# STM32U3B5xx register map
File version: 1.0
Registers are 32-bit, read-write, reset 0x0 unless marked. A register's access mark holds for its fields unless they carry their own. Offsets are from the block's base; [hi:lo] are bit positions; lines under a group give offsets from that group; {n}, {i} and the like mark numbered series; <NAME> marks a mode.

## HSP1 — HSP
Base 0x4002C000
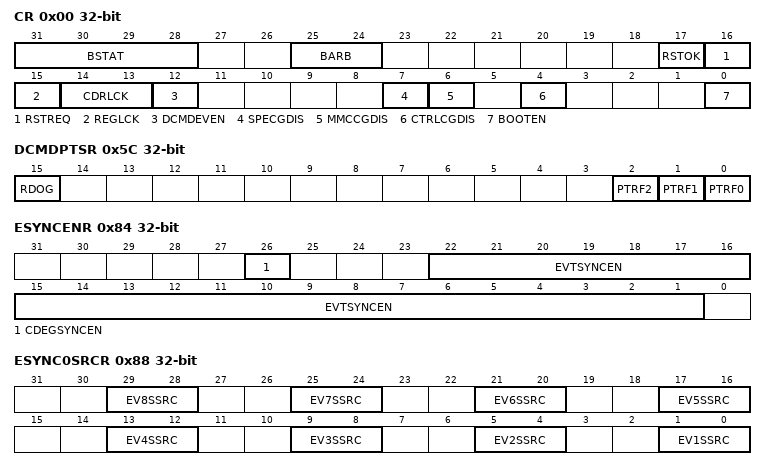
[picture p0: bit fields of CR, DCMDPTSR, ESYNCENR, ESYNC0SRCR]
0x00 CR — HSP control register
  [31:28] BSTAT — BSTAT[3:0] bits (Boot status)
  [25:24] BARB — BARB[1:0] bits (BRAM Arbitration)
  [17] RSTOK — RSTOK (Reset request accepted)
  [16] RSTREQ — RSTREQ (Reset request)
  [15] REGLCK — REGLCK (Register write lock access control)
  [14:13] CDRLCK — CDRLCK[1:0] bits (CRAM & DRAM lock access control)
  [12] DCMDEVEN — DCMDEVEN (Direct command event enable)
  [7] SPECGDIS — SPECGDIS (SPE clock gating disable)
  [6] MMCCGDIS — MMCCGDIS (MMC clock gating disable)
  [4] CTRLCGDIS — CTRLCGDIS (HSP_CTRL clock gating disable)
  [0] BOOTEN — BOOTEN (Boot Enable control)
0x40 C2HSEMR — HSP CPU to HSP semaphore register
  [0] C2HSEM — C2HSEM (CPU to HSP semaphore)
0x44 C2HMSGDR — HSP CPU to HSP message data register
  [31:0] C2HDATA — C2HDATA[31:0] bits (CPU Message for the HSP)
0x48 H2CSEMR — HSP HSP to CPU semaphore register
  [0] H2CSEM — H2CSEM (HSP to CPU semaphore)
0x4C H2CMSGDR — HSP HSP to CPU message data register
  [31:0] H2CDATA — H2CDATA[31:0] bits (HSP Message for the CPU)
0x58 DCMDSR — HSP DCMD Command status register
  [0] DCBSY — DCBSY (Direct command busy flag)
0x5C DCMDPTSR — HSP DCMD Pointer status register
  [15] RDOG — RDOG (Read on-going indicator)
  [2] PTRF2 — PTRF2 (Address pointer 2 flag)
  [1] PTRF1 — PTRF1 (Address pointer 1 flag)
  [0] PTRF0 — PTRF0 (Address pointer 0 flag)
0x60 DCMDIDR — HSP DCMD Command ID register
  [15:0] CMDID — CMDID[15:0] bits (Command ID)
{0x64+4i} DCMDPTR{i} (i=0..2) — HSP DCMD address pointer register {i}
  [31:0] PTCPU — PTCPU[31:0] bits (Address pointer value)
0x80 EVTENR — HSP event enable register
  [22:1] EVTEN — EVTEN[21:0] bits (Events enable)
0x84 ESYNCENR — HSP Event synchronization enable register
  [26] CDEGSYNCEN — CDEGSYNCEN (CPU dedicated event synchronization enable)
  [22:1] EVTSYNCEN — EVTSYNCEN[21:0] bits (Event synchronization enable)
0x88 ESYNC0SRCR — HSP Event synchronization source register 0
  [4n-3:4n-4] EV{n}SSRC (n=1..8) — EV{n}SSRC[1:0] bits (Event {n} synchronization source)
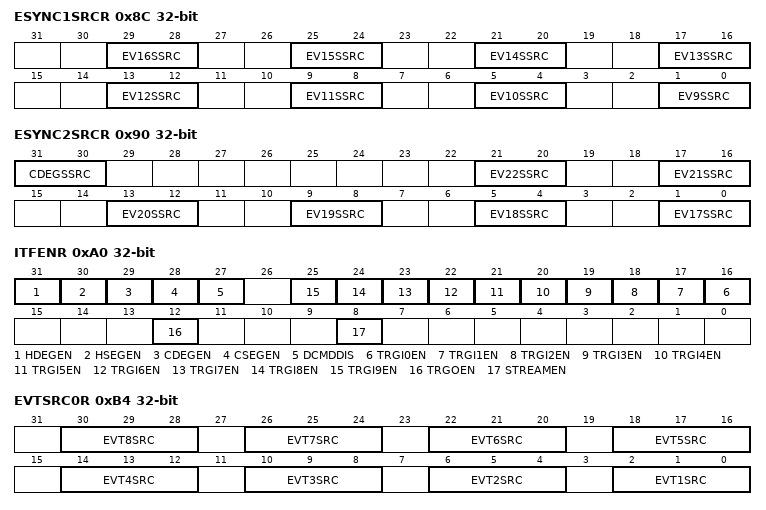
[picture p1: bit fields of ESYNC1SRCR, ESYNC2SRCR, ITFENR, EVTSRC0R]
0x8C ESYNC1SRCR — HSP Event synchronization source register 1
  [4n-35:4n-36] EV{n}SSRC (n=9..16) — EV{n}SSRC[1:0] bits (Event {n} synchronization source)
0x90 ESYNC2SRCR — HSP Event synchronization source register 2
  [31:30] CDEGSSRC — CDEGSSRC[1:0] bits (CPU dedicated event synchronization source)
  [4n-67:4n-68] EV{n}SSRC (n=17..22) — EV{n}SSRC[1:0] bits (Event {n} synchronization source)
0x98 PEVTLR — HSP pending event level register
  [27:0] EVTL — EVTL[27:0] bits (Event level)
0xA0 ITFENR — HSP interfaces enable register
  [31] HDEGEN — HDEGEN (HDEG interface enable bit )
  [30] HSEGEN — HSEGEN (HSEG interface enable bit )
  [29] CDEGEN — CDEGEN (CDEG interface enable bit )
  [28] CSEGEN — CSEGEN (CSEG interface enable bit <sup>(1)</sup>)
  [27] DCMDDIS — DCMDDIS (Direct command interface disable bit )
  [n+16] TRGI{n}EN (n=0..9) — TRGI{n}EN (TRGIN{n} enable bit <sup>(1)</sup>)
  [12] TRGOEN — TRGOEN (TRGO enable bit <sup>(1)</sup>)
  [8] STREAMEN — STREAMEN (STREAMITF enable <sup>(1)</sup>)
0xB4 EVTSRC0R — HSP Event source register 0
  [4n-2:4n-4] EVT{n}SRC (n=1..8) — EVT{n}SRC[2:0] bits (Event source selection for priority encoder input {n})
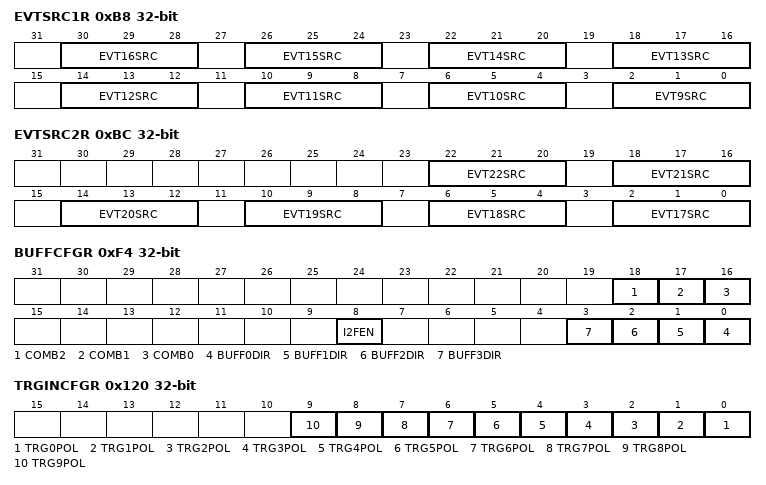
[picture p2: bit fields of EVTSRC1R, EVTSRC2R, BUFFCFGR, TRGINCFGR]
0xB8 EVTSRC1R — HSP Event source register 1
  [4n-34:4n-36] EVT{n}SRC (n=9..16) — EVT{n}SRC[2:0] bits (Event source selection for priority encoder input {n})
0xBC EVTSRC2R — HSP Event source register 2
  [4n-66:4n-68] EVT{n}SRC (n=17..22) — EVT{n}SRC[2:0] bits (Event source selection for priority encoder input {n})
0xF4 BUFFCFGR — HSP BUFF configuration register
  [18] COMB2 — COMB2 (BUFCMB control for buff_evt[2] )
  [17] COMB1 — COMB1 (BUFCMB control for buff_evt[1] <sup>(1)</sup>)
  [16] COMB0 — COMB0 (BUFCMB control for buff_evt[0] <sup>(1)</sup>)
  [8] I2FEN — I2FEN (integer to float32 conversion <sup>(1)</sup>)
  [n] BUFF{n}DIR (n=0..3) — BUFF{n}DIR (Direction selection of BUFF{n} <sup>(1)</sup>)
{0xF8+4i} BUFFDR{i} (i=0..3) — HSP BUFF data register array
  [31:0] BUFFDAT — BUFFDAT[31:0] bits (Data buffer)
0x120 TRGINCFGR — HSP TRGIN configuration register
  [n] TRG{n}POL (n=0..9) — TRG{n}POL (Polarity selection for TRGIN{n})
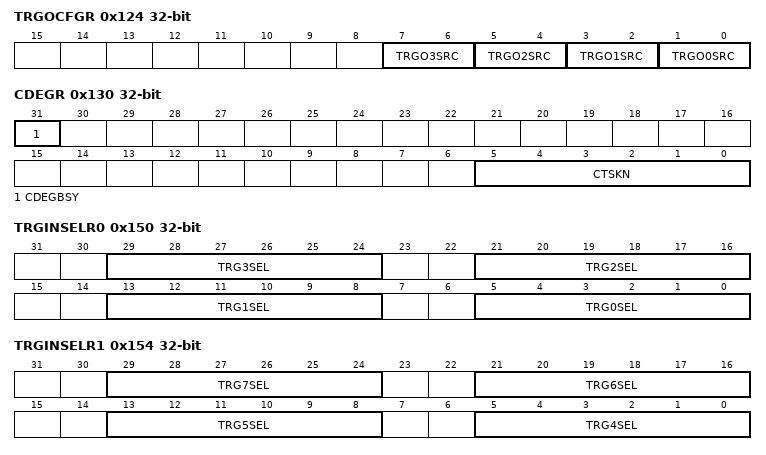
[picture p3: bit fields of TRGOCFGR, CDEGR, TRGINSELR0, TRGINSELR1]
0x124 TRGOCFGR — HSP TRGO configuration register
  [7:6] TRGO3SRC — TRGO3SRC[1:0] bits (Trigger source selection for hsp_trg_out[3] )
  [5:4] TRGO2SRC — TRGO2SRC[1:0] bits (Trigger source selection for hsp_trg_out[2] <sup>(1)</sup>)
  [3:2] TRGO1SRC — TRGO1SRC[1:0] bits (Trigger source selection for hsp_trg_out[1] <sup>(1)</sup>)
  [1:0] TRGO0SRC — TRGO0SRC[1:0] bits (Trigger source selection for hsp_trg_out[0] <sup>(1)</sup>)
0x12C CSEGR — HSP CPU shared event generator register
  [22:1] CSEVT — CSEVT[21:0] bits (CPU Shared Software Event )
0x130 CDEGR — HSP CPU dedicated event generation register
  [31] CDEGBSY — CDEGBSY (CPU dedicated event generator busy)
  [5:0] CTSKN — CTSKN[5:0] bits (CPU Task number)
0x150 TRGINSELR0 — HSP TRGIN input selection register 0
  [8n+5:8n] TRG{n}SEL (n=0..3) — TRG{n}SEL[5:0] bits (Input trigger selection for TRGIN{n})
0x154 TRGINSELR1 — HSP TRGIN input selection register 1
  [8n-27:8n-32] TRG{n}SEL (n=4..7) — TRG{n}SEL[5:0] bits (Input trigger selection for TRGIN{n})
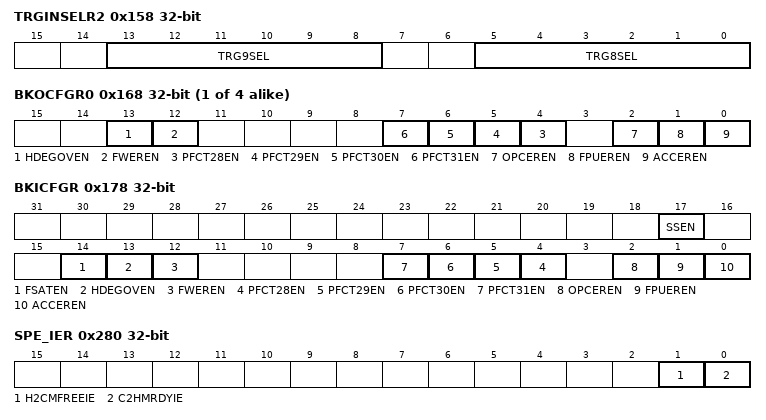
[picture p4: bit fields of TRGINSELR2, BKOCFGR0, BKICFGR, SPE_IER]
0x158 TRGINSELR2 — HSP TRGIN input selection register 2
  [13:8] TRG9SEL — TRG9SEL[5:0] bits (Input trigger selection for TRGIN9)
  [5:0] TRG8SEL — TRG8SEL[5:0] bits (Input trigger selection for TRGIN8)
{0x168+4i} BKOCFGR{i} (i=0..3) — HSP break output configuration register 0-3
  [13] HDEGOVEN — HDEGOVEN (HSP dedicated event generator overrun break enable for HDEGOVRF <sup>(1)</sup>)
  [12] FWEREN — FWEREN (Firmware error break enable for FWERRF <sup>(1)</sup>)
  [n-24] PFCT{n}EN (n=28..31) — PFCT{n}EN (Processing function flag break enable for PFCTF[{n}] <sup>(1)</sup>)
  [2] OPCEREN — OPCEREN (Opcode error break enable for OPCOERRF )
  [1] FPUEREN — FPUEREN (FPU error break enable for FPUERRF <sup>(1)</sup>)
  [0] ACCEREN — ACCEREN (Access error break enable for ACCERRF <sup>(1)</sup>)
0x178 BKICFGR — HSP break input configuration register
  [17] SSEN — SSEN (Single step enable <sup>(1)</sup>)
  [14] FSATEN — FSATEN (FPU saturation break enable for FPUSATF <sup>(1)</sup>)
  [13] HDEGOVEN — HDEGOVEN (HSP dedicated event generator overrun break enable for HDEGOVRF <sup>(1)</sup>)
  [12] FWEREN — FWEREN (Firmware error break enable for FWERRF <sup>(1)</sup>)
  [n-24] PFCT{n}EN (n=28..31) — PFCT{n}EN (Processing function flag break enable for PFCTF[{n}] <sup>(1)</sup>)
  [2] OPCEREN — OPCEREN (Opcode error break enable for OPCOERRF )
  [1] FPUEREN — FPUEREN (FPU error break enable for FPUERRF <sup>(1)</sup>)
  [0] ACCEREN — ACCEREN (Access error break enable for ACCERRF <sup>(1)</sup>)
0x188 FWERR — HSP firmware error register
  [9:0] FWERRN — FWERRN[9:0] bits (Firmware error number)
{0x194+4i} PARAMR{i} (i=0..15) — HSP parameter register {i}
  [31:0] PARAM — PARAM[31:0] bits (Parameter value)
0x280 SPE_IER — HSP SPE interrupt enable register
  [1] H2CMFREEIE — H2CMFREEIE (SPE to CPU message free interrupt enable)
  [0] C2HMRDYIE — C2HMRDYIE (CPU to SPE message ready interrupt enable)
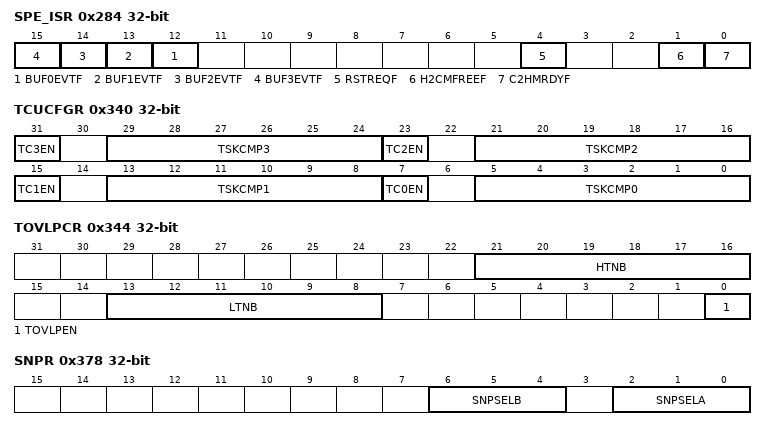
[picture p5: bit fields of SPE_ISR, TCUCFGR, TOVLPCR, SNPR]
0x284 SPE_ISR — HSP SPE interrupt status register
  [n+12] BUF{n}EVTF (n=0..3) — BUF{n}EVTF (BUF{n} status)
  [4] RSTREQF — RSTREQF (HSP reset request)
  [1] H2CMFREEF — H2CMFREEF (SPE to CPU message box status)
  [0] C2HMRDYF — C2HMRDYF (CPU to SPE message box status)
0x340 TCUCFGR — HSP task comparator unit register
  [31] TC3EN — TC3EN (Task comparator 3 enable )
  [8n+5:8n] TSKCMP{n} (n=0..3) — TSKCMP{n}[5:0] bits (Task compare {n} <sup>(1)</sup>)
  [23] TC2EN — TC2EN (Task comparator 2 enable <sup>(1)</sup>)
  [15] TC1EN — TC1EN (Task comparator 1 enable <sup>(1)</sup>)
  [7] TC0EN — TC0EN (Task comparator 0 enable <sup>(1)</sup>)
0x344 TOVLPCR — HSP task overlap control register
  [21:16] HTNB — HTNB[5:0] bits (Higher task number value )
  [13:8] LTNB — LTNB[5:0] bits (Lower task number value <sup>(1)</sup>)
  [0] TOVLPEN — TOVLPEN (Task overlap enable <sup>(1)</sup>)
0x378 SNPR — HSP snoop register
  [6:4] SNPSELB — SNPSELB[2:0] bits (Snoop group B signal selection)
  [2:0] SNPSELA — SNPSELA[2:0] bits (Snoop group A signal selection)
0x37C CCNTR — HSP conflict counter register
  [31:0] CCNTR — CCNTR[31:0] bits (Conflict counter)
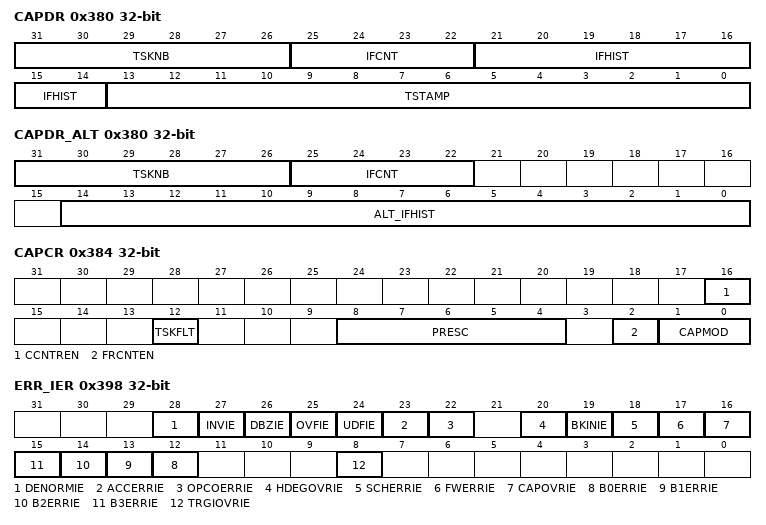
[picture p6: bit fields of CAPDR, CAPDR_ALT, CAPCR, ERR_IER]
0x380 CAPDR — HSP data capture register
  [31:26] TSKNB — Last captured task number
  [25:22] IFCNT — IF instruction counter
  [21:14] IFHIST — IF condition history
  [13:0] TSTAMP — Time-stamp value
0x380 CAPDR_ALT (alternate view of CAPDR) — HSP data capture register
  [31:26] TSKNB — Last captured task number
  [25:22] IFCNT — IF instruction counter
  [14:0] ALT_IFHIST — IF condition history
0x384 CAPCR — HSP capture control register
  [16] CCNTREN — CCNTREN (Conflict counter enable )
  [12] TSKFLT — TSKFLT (Task filter enable <sup>(1)</sup>)
  [8:4] PRESC — PRESC[4:0] bits (Time-stamp prescaler value )
  [2] FRCNTEN — FRCNTEN (Free-running counter enable )
  [1:0] CAPMOD — CAPMOD[1:0] bits (Capture mode )
0x398 ERR_IER — HSP error interrupt enable register
  [28] DENORMIE — DENORMIE (FPU denormal interrupt enable)
  [27] INVIE — INVIE (FPU Invalid exception interrupt enable)
  [26] DBZIE — DBZIE (FPU division-by-zero exception interrupt enable)
  [25] OVFIE — OVFIE (FPU Overflow exception interrupt enable)
  [24] UDFIE — UDFIE (FPU Underflow exception interrupt enable)
  [23] ACCERRIE — ACCERRIE (SPE access error interrupt enable)
  [22] OPCOERRIE — OPCOERRIE (Invalid Op. code error interrupt enable)
  [20] HDEGOVRIE — HDEGOVRIE (SPE event overrun interrupt enable)
  [19] BKINIE — BKINIE (Break input interrupt enable)
  [18] SCHERRIE — SCHERRIE (Scheduler error interrupt enable)
  [17] FWERRIE — FWERRIE (Firmware error interrupt enable)
  [16] CAPOVRIE — CAPOVRIE (Capture register overrun interrupt enable)
  [n+12] B{n}ERRIE (n=0..3) — B{n}ERRIE (H2CBUFF{n} underrun or C2HBUFF{n} overrun interrupt enable)
  [8] TRGIOVRIE — TRGIOVRIE (TRGITF overrun interrupt enable)
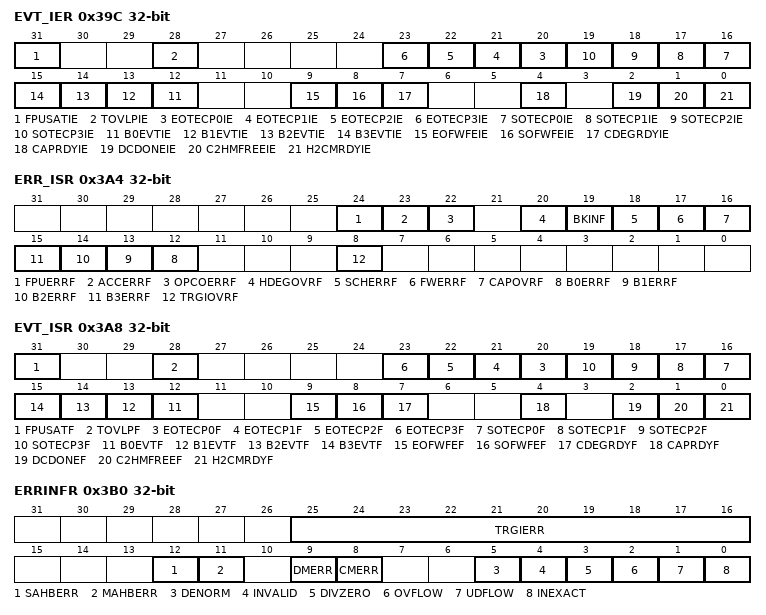
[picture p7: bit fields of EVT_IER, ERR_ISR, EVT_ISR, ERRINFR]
0x39C EVT_IER — HSP events interrupt enable register
  [31] FPUSATIE — FPUSATIE (Saturation flag interrupt enable)
  [28] TOVLPIE — TOVLPIE (Task overlap flag interrupt enable)
  [n+20] EOTECP{n}IE (n=0..3) — EOTECP{n}IE (End of task generated by event comparator {n} interrupt enable)
  [n+16] SOTECP{n}IE (n=0..3) — SOTECP{n}IE (Start of task generated by event comparator {n} interrupt enable)
  [n+12] B{n}EVTIE (n=0..3) — B{n}EVTIE (BUFF{n} event interrupt enable)
  [9] EOFWFEIE — EOFWFEIE (End of WFE interrupt enable)
  [8] SOFWFEIE — SOFWFEIE (Start of WFE interrupt enable)
  [7] CDEGRDYIE — CDEGRDYIE (CPU Dedicated event generator ready interrupt enable)
  [4] CAPRDYIE — CAPRDYIE (Capture buffer data ready interrupt enable)
  [2] DCDONEIE — DCDONEIE (Direct command done interrupt enable)
  [1] C2HMFREEIE — C2HMFREEIE (CPU to HSP message box free interrupt enable)
  [0] H2CMRDYIE — H2CMRDYIE (HSP to CPU message ready interrupt enable)
0x3A0 PFCTEVT_IER — HSP processing event interrupt enable register
  [31:0] PFCTIE — PFCTIE[31:0] bits (Processing function flags interrupt enable)
0x3A4 ERR_ISR — HSP error interrupt status register
  [24] FPUERRF — FPUERRF (Computation error flag)
  [23] ACCERRF — ACCERRF (SPE Access error flag)
  [22] OPCOERRF — OPCOERRF (Invalid OpCode error flag)
  [20] HDEGOVRF — HDEGOVRF (SPE event overrun flag)
  [19] BKINF — BKINF (Break input flag)
  [18] SCHERRF — SCHERRF (Scheduler error flag)
  [17] FWERRF — FWERRF (Firmware error flag)
  [16] CAPOVRF — CAPOVRF (Capture register overrun flag)
  [n+12] B{n}ERRF (n=0..3) — B{n}ERRF (H2CBUFF{n} underrun or C2HBUFF{n} overrun flag)
  [8] TRGIOVRF — TRGIOVRF (TRGITF overrun flag)
0x3A8 EVT_ISR — HSP events interrupt status register
  [31] FPUSATF — FPUSATF (FPU saturation flag)
  [28] TOVLPF — TOVLPF (Task overlap flag)
  [n+20] EOTECP{n}F (n=0..3) — EOTECP{n}F (End of task flag, for event comparator {n})
  [n+16] SOTECP{n}F (n=0..3) — SOTECP{n}F (Start of task flag, for event comparator {n})
  [n+12] B{n}EVTF (n=0..3) — B{n}EVTF (BUFF{n} event flag)
  [9] EOFWFEF — EOFWFEF (End of WFE flag)
  [8] SOFWFEF — SOFWFEF (Start of WFE flag)
  [7] CDEGRDYF — CDEGRDYF (CPU Dedicated event generator ready flag)
  [4] CAPRDYF — CAPRDYF (Capture buffer data ready flag)
  [2] DCDONEF — DCDONEF (Direct command done flag)
  [1] C2HMFREEF — C2HMFREEF (CPU to HSP message box free flag)
  [0] H2CMRDYF — H2CMRDYF (HSP to CPU message ready flag)
0x3AC PFCTEVT_ISR — HSP processing event interrupt status register
  [31:0] PFCTF — PFCTF[31:0] bits (Flags generated by SPE processing functions )
0x3B0 ERRINFR — HSP error information register
  [25:16] TRGIERR — TRGIERR[9:0] bits (TRGIN error information)
  [12] SAHBERR — SAHBERR (Slave AHB access error flag)
  [11] MAHBERR — MAHBERR (Internal AHB access error flag)
  [9] DMERR — DMERR (Data memory access error flag)
  [8] CMERR — CMERR (Code memory access error flag)
  [5] DENORM — DENORM (DENORMAL exception flag)
  [4] INVALID — INVALID (INVALID exception flag)
  [3] DIVZERO — DIVZERO (Division by zero exception flag)
  [2] OVFLOW — OVFLOW (OVERFLOW exception flag)
  [1] UDFLOW — UDFLOW (UNDERFLOW exception flag)
  [0] INEXACT — INEXACT (INEXACT exception flag)
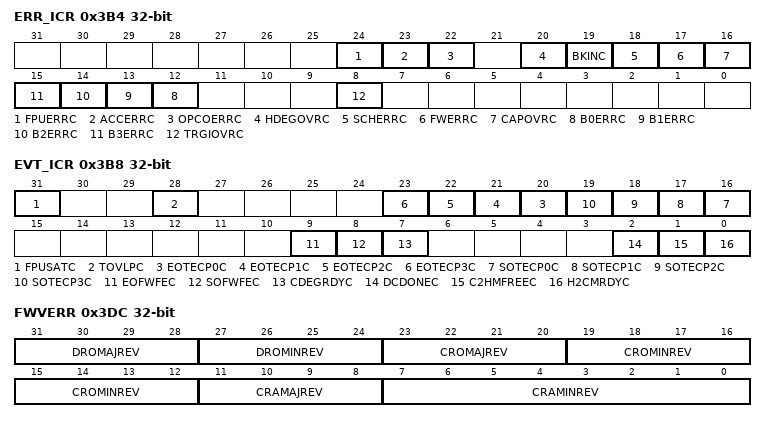
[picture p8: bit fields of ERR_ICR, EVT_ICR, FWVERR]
0x3B4 ERR_ICR — HSP error interrupt clear register
  [24] FPUERRC — FPUERRC (Clear FPUERRF flag)
  [23] ACCERRC — ACCERRC (Clear ACCERRF flag)
  [22] OPCOERRC — OPCOERRC (Clear OPCOERRF flag)
  [20] HDEGOVRC — HDEGOVRC (Clear HDEGOVRF flag)
  [19] BKINC — BKINC (Clear BKINF flag)
  [18] SCHERRC — SCHERRC (Clear SCHERRF flag)
  [17] FWERRC — FWERRC (Clear FWERRF flag)
  [16] CAPOVRC — CAPOVRC (Clear CAPOVRF flag)
  [n+12] B{n}ERRC (n=0..3) — B{n}ERRC (Clear B{n}ERRF flag)
  [8] TRGIOVRC — TRGIOVRC (Clear TRGIOVRF flag)
0x3B8 EVT_ICR — HSP events Interrupt clear register
  [31] FPUSATC — FPUSATC (Clear FPUSATF flag)
  [28] TOVLPC — TOVLPC (Clear TOVLPF flag)
  [n+20] EOTECP{n}C (n=0..3) — EOTECP{n}C (Clear EOTECP{n}F flag)
  [n+16] SOTECP{n}C (n=0..3) — SOTECP{n}C (Clear SOTECP{n}F flag)
  [9] EOFWFEC — EOFWFEC (Clear of EOFWFEF flag)
  [8] SOFWFEC — SOFWFEC (Clear of SOFWFEF flag)
  [7] CDEGRDYC — CDEGRDYC (Clear of CDEGRDYF flag)
  [2] DCDONEC — DCDONEC (Clear DCDONEF flag)
  [1] C2HMFREEC — C2HMFREEC (Clear C2HMFREEF flag)
  [0] H2CMRDYC — H2CMRDYC (Clear H2CMRDYF flag)
0x3BC PFCTEVT_ICR — HSP processing event interrupt clear register
  [31:0] PFCTC — PFCTC[31:0] bits (Clear PFCTF[31:0] flag)
0x3DC FWVERR — HSP firmware versions register
  [31:28] DROMAJREV — DROMAJREV[3:0] bits (Data ROM Major revision)
  [27:24] DROMINREV — DROMINREV[3:0] bits (Data ROM Minor revision)
  [23:20] CROMAJREV — CROMAJREV[3:0] bits (Code ROM Major revision)
  [19:12] CROMINREV — CROMINREV[7:0] bits (Code ROM Minor revision)
  [11:8] CRAMAJREV — CRAMAJREV[3:0] bits (Code RAM Major revision)
  [7:0] CRAMINREV — CRAMINREV[7:0] bits (Code RAM Minor revision)
